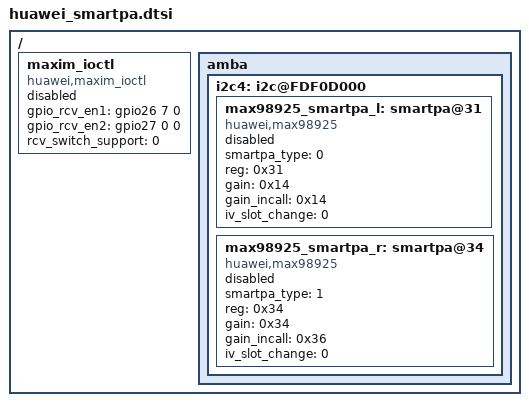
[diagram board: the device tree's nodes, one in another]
/ {
	maxim_ioctl {
		compatible = "huawei,maxim_ioctl";
		gpio_rcv_en1 = <&gpio26 7 0>;
		gpio_rcv_en2 = <&gpio27 0 0>;
		rcv_switch_support = <0>;
		status = "disabled";

	};

	amba {
		i2c4: i2c@FDF0D000 {
			max98925_smartpa_l:smartpa@31 {
				compatible = "huawei,max98925";
				smartpa_type = <0>; //left smartPA
				reg = <0x31>;
				gain = <0x14>;
				gain_incall = <0x14>; //spk's is same as gain
				iv_slot_change = <0>;
				status = "disabled";
			};
			max98925_smartpa_r:smartpa@34 {
				compatible = "huawei,max98925";
				smartpa_type = <1>; //right smartPA
				reg = <0x34>;
				gain = <0x34>;
				gain_incall = <0x36>;
				iv_slot_change = <0>;
				status = "disabled";
			};
		};
	};
};
